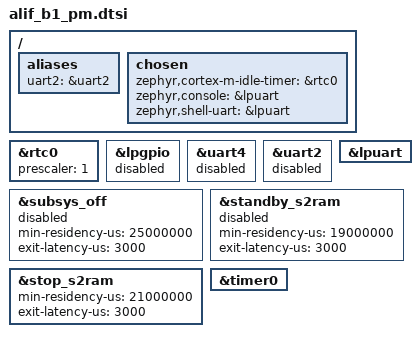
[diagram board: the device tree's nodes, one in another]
/*
 * Copyright (c) 2024 Alif Semiconductor
 * SPDX-License-Identifier: Apache-2.0
 */

/*
 * Enable RTC and Set the counter to increment every 1sec
 */

&rtc0 {
	prescaler = <1>;
	status = "okay";
};

&lpgpio {
	status = "disabled";
};

&uart4 {
	status = "disabled";
	
};

&uart2 {
	status = "disabled";
	
};


&lpuart {
	status = "okay";
};


&subsys_off {
	min-residency-us = <25000000>;
	exit-latency-us = <3000>;
	status = "disabled";
};

&standby_s2ram {
	min-residency-us = <19000000>;
	exit-latency-us = <3000>;
	status = "disabled";
};

&stop_s2ram {
	min-residency-us = <21000000>;
	exit-latency-us = <3000>;
	status = "okay";
};

&timer0{
	status = "okay";
};


/ {
aliases {
    uart2 = &uart2;
   };
};


/ {
	chosen {
		zephyr,cortex-m-idle-timer = &rtc0;
		zephyr,console = &lpuart;
	        zephyr,shell-uart = &lpuart;
	       // zephyr,console = &uart2;
	        //zephyr,shell-uart = &uart2;
	};
	/*power-states {
		off: off {
			/* 4ms is time reserved for os wakeup and sleep */
			//min-residency-us = < 4000 >;
		//};*/
	//};
	//zephyr,console = &uart2;

};
